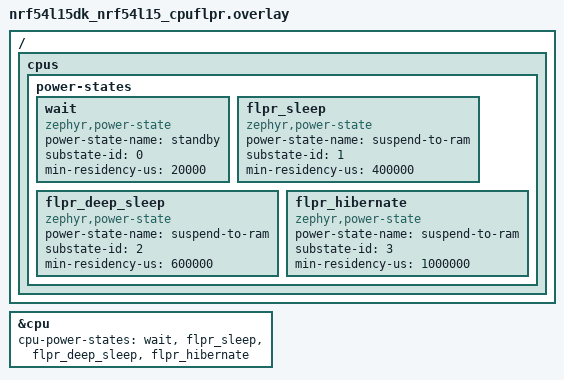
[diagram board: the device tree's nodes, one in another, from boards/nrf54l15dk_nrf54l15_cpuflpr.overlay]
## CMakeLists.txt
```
cmake_minimum_required(VERSION 3.20.0)

find_package(Zephyr REQUIRED HINTS $ENV{ZEPHYR_BASE})
project(remote)

message(DEBUG "Power mode handler for RISC-V is included.")
target_sources(app PRIVATE src/power_off.c)
target_sources(app PRIVATE src/main_flpr.c)
```

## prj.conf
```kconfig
CONFIG_LOG=y
CONFIG_CONSOLE=y
CONFIG_UART_CONSOLE=y
CONFIG_SERIAL=y
CONFIG_BOOT_BANNER=n
CONFIG_NCS_BOOT_BANNER=n
CONFIG_PRINTK=y

CONFIG_ASSERT=y
CONFIG_GPIO=y

CONFIG_PM=y
CONFIG_POWEROFF=y
CONFIG_PM_DEVICE=y
CONFIG_PM_DEVICE_RUNTIME=y
```

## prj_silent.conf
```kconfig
# Silent build - no logging overhead during power measurements.
CONFIG_LOG=n
CONFIG_CONSOLE=n
CONFIG_UART_CONSOLE=n
CONFIG_SERIAL=n
CONFIG_BOOT_BANNER=n
CONFIG_NCS_BOOT_BANNER=n

CONFIG_ASSERT=y
CONFIG_GPIO=y

CONFIG_PM=y
CONFIG_POWEROFF=y
CONFIG_PM_DEVICE=y
CONFIG_PM_DEVICE_RUNTIME=y
```

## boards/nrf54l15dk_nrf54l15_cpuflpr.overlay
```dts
/*
 * Copyright (c) 2025 Nordic Semiconductor ASA
 *
 * SPDX-License-Identifier: LicenseRef-Nordic-5-Clause
 */

/ {
	cpus {
		power-states {
			wait: wait {
				compatible = "zephyr,power-state";
				power-state-name = "standby";
				substate-id = <0>;
				min-residency-us = <20000>;
			};

			flpr_sleep: flpr_sleep {
				compatible = "zephyr,power-state";
				power-state-name = "suspend-to-ram";
				substate-id = <1>;
				min-residency-us = <400000>;
			};

			flpr_deep_sleep: flpr_deep_sleep {
				compatible = "zephyr,power-state";
				power-state-name = "suspend-to-ram";
				substate-id = <2>;
				min-residency-us = <600000>;
			};

			flpr_hibernate: flpr_hibernate {
				compatible = "zephyr,power-state";
				power-state-name = "suspend-to-ram";
				substate-id = <3>;
				min-residency-us = <1000000>;
			};
		};
	};
};

&cpu {
	cpu-power-states = <&wait &flpr_sleep &flpr_deep_sleep &flpr_hibernate>;
};
```

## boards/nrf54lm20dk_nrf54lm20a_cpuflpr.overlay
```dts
/*
 * Copyright (c) 2025 Nordic Semiconductor ASA
 *
 * SPDX-License-Identifier: LicenseRef-Nordic-5-Clause
 */

/ {
	cpus {
		power-states {
			wait: wait {
				compatible = "zephyr,power-state";
				power-state-name = "standby";
				substate-id = <0>;
				min-residency-us = <2000>;
			};

			flpr_sleep: flpr_sleep {
				compatible = "zephyr,power-state";
				power-state-name = "suspend-to-ram";
				substate-id = <1>;
				min-residency-us = <400000>;
			};

			flpr_deep_sleep: flpr_deep_sleep {
				compatible = "zephyr,power-state";
				power-state-name = "suspend-to-ram";
				substate-id = <2>;
				min-residency-us = <600000>;
			};

			flpr_hibernate: flpr_hibernate {
				compatible = "zephyr,power-state";
				power-state-name = "suspend-to-ram";
				substate-id = <3>;
				min-residency-us = <1000000>;
			};
		};
	};
};

&cpu {
	cpu-power-states = <&wait &flpr_sleep &flpr_deep_sleep &flpr_hibernate>;
};
```

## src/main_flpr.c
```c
#include <zephyr/kernel.h>
#include <zephyr/logging/log.h>
#include <zephyr/drivers/gpio.h>

LOG_MODULE_REGISTER(flpr_sleep_test, LOG_LEVEL_INF);

/*
 * FLPR core image - shared by nRF54H20, nRF54LM20A and nRF54L15.
 *
 * Active phase: quadratic computation (ax² + bx + c) to simulate a
 * realistic RISC-V workload using MUL/ADD instructions.
 * Tune COMPUTE_ITERATIONS to achieve ~1-2 ms active time at the FLPR
 * clock frequency - verify the pulse width on a PPK trace.
 *
 * PM selects the sleep state based on TEST_SLEEP_DURATION_MS vs the
 * min-residency-us values defined in the board FLPR overlay:
 *   300 ms  -> WAIT        (substate 0, min-residency  20 ms)
 *   500 ms  -> SLEEP       (substate 1, min-residency 400 ms)
 *   800 ms  -> DEEP_SLEEP  (substate 2, min-residency 600 ms)
 *   1200 ms -> HIBERNATE   (substate 3, min-residency 1000 ms)
 *
 * Note: nRF54H20 FLPR has only two power states (wait / suspend-to-ram).
 *
 * Baseline mode (CONFIG_TEST_BASELINE_SLEEP=y):
 *   FLPR sleeps forever - no compute, no GRTC wakeup.  Used to measure
 *   the true system current floor.
 */



#define COMPUTE_ITERATIONS 65000
#define BUSY_WAIT_INTERVAL 5000

static const struct gpio_dt_spec boot_led = GPIO_DT_SPEC_GET(DT_ALIAS(led0), gpios);

int main(void)
{
#if defined(CONFIG_TEST_BASELINE_SLEEP)
	while (1) {
		k_sleep(K_FOREVER);
	}
#else
	int counter = 0;

	/* Brief LED flash on boot so FLPR startup is visible on a PPK trace. */
	if (gpio_is_ready_dt(&boot_led)) {
		gpio_pin_configure_dt(&boot_led, GPIO_OUTPUT_INACTIVE);
		gpio_pin_set_dt(&boot_led, 1);
		k_busy_wait(5000); /* 5 ms */
		gpio_pin_set_dt(&boot_led, 0);
	}

	LOG_INF("Multicore flpr_sleep_test on %s", CONFIG_BOARD_TARGET);
	LOG_INF("Main sleeps for %d ms", CONFIG_TEST_SLEEP_DURATION_MS);

	while (1) {
		volatile uint32_t result = 0;

		for (uint32_t i = 0; i < COMPUTE_ITERATIONS; i++) {
			result += (i * i) + (3 * i) + 7;
		}

		LOG_INF("Run %d (result=%u)", counter, (unsigned int)result);
		counter++;
		/*
		k_busy_wait(BUSY_WAIT_INTERVAL);
		*/
		k_msleep(CONFIG_TEST_SLEEP_DURATION_MS);
	}
#endif /* CONFIG_TEST_BASELINE_SLEEP */

	return 0;
}
```

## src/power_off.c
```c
#include <zephyr/kernel.h>
#include <zephyr/pm/pm.h>
#include <zephyr/devicetree.h>
#include <hal/nrf_vpr_csr.h>

#include <zephyr/logging/log.h>
LOG_MODULE_REGISTER(power_off, LOG_LEVEL_INF);

#define VIPER_SLEEP_SUBSTATE_WAIT 0

#if defined(CONFIG_SOC_NRF54H20_CPUFLPR)
/* nRF54H20 FLPR has two sleep states:
 *   0 = HIBERNATE  (PM_STATE_SUSPEND_TO_RAM)  context saved, core resets on wakeup
 *   1 = DEEPSLEEP  (PM_STATE_SUSPEND_TO_RAM)  noop
 */
#define VIPER_SLEEP_SUBSTATE_HIBERNATE 0
#define VIPER_SLEEP_SUBSTATE_DEEPSLEEP 1
#else
/* All other FLPR cores (nRF54LM20A, nRF54L15) have four sleep states:
 *   0 = WAIT       (PM_STATE_STANDBY)         clock gated, fast wakeup
 *   1 = SLEEP      (PM_STATE_SUSPEND_TO_RAM)  clock off, RAM on, resumable
 *   2 = DEEP_SLEEP (PM_STATE_SUSPEND_TO_RAM)  clock off, RAM retained, resumable
 *   3 = HIBERNATE  (PM_STATE_SUSPEND_TO_RAM)  power off, context saved, resets on wakeup
 */
#define VIPER_SLEEP_SUBSTATE_SLEEP      1
#define VIPER_SLEEP_SUBSTATE_DEEP_SLEEP 2
#define VIPER_SLEEP_SUBSTATE_HIBERNATE  3
#endif

static void pm_go_to_wait(void)
{
	LOG_INF("Wait state");

	csr_write(VPRCSR_NORDIC_VPRNORDICSLEEPCTRL,
		  VPRCSR_NORDIC_VPRNORDICSLEEPCTRL_SLEEPSTATE_WAIT);
	nrf_barrier_w();
	arch_cpu_idle();
}

#if !defined(CONFIG_SOC_NRF54H20_CPUFLPR)
static void pm_go_to_sleep(void)
{
	LOG_INF("Sleep state");

	csr_write(VPRCSR_NORDIC_VPRNORDICSLEEPCTRL,
		  VPRCSR_NORDIC_VPRNORDICSLEEPCTRL_SLEEPSTATE_SLEEP);
	nrf_barrier_w();
	arch_cpu_idle();
}

static void pm_go_to_deep_sleep(void)
{
	LOG_INF("Deep sleep state");

	csr_write(VPRCSR_NORDIC_VPRNORDICSLEEPCTRL,
		  VPRCSR_NORDIC_VPRNORDICSLEEPCTRL_SLEEPSTATE_DEEPSLEEP);
	nrf_barrier_w();
	arch_cpu_idle();
}
#endif

static void pm_go_to_hibernate(void)
{
	LOG_INF("Hibernate state (core resets on wakeup)");

	csr_write(VPRCSR_NORDIC_VPRNORDICSLEEPCTRL,
		  VPRCSR_NORDIC_VPRNORDICSLEEPCTRL_SLEEPSTATE_HIBERNATE);
	nrf_barrier_w();
	arch_cpu_idle();
}

void pm_state_set(enum pm_state state, uint8_t substate_id)
{
	LOG_INF("pm_state_set: %d %d", (int)state, (int)substate_id);

	switch (state) {
	case PM_STATE_STANDBY:
		switch (substate_id) {
		case VIPER_SLEEP_SUBSTATE_WAIT:
			pm_go_to_wait();
			break;
		}
		break;
	case PM_STATE_SUSPEND_TO_RAM:
		switch (substate_id) {
#if defined(CONFIG_SOC_NRF54H20_CPUFLPR)
		case VIPER_SLEEP_SUBSTATE_HIBERNATE:
			pm_go_to_hibernate();
			break;
		case VIPER_SLEEP_SUBSTATE_DEEPSLEEP:
			/* noop */
			break;
#else
		case VIPER_SLEEP_SUBSTATE_SLEEP:
			pm_go_to_sleep();
			break;
		case VIPER_SLEEP_SUBSTATE_DEEP_SLEEP:
			pm_go_to_deep_sleep();
			break;
		case VIPER_SLEEP_SUBSTATE_HIBERNATE:
			pm_go_to_hibernate();
			break;
#endif
		}
		break;
	default:
		break;
	}
}

void pm_state_exit_post_ops(enum pm_state state, uint8_t substate_id)
{
	LOG_INF("pm_state_exit_post_ops");
	ARG_UNUSED(state);
	ARG_UNUSED(substate_id);

	csr_write(VPRCSR_NORDIC_VPRNORDICSLEEPCTRL,
		  VPRCSR_NORDIC_VPRNORDICSLEEPCTRL_SLEEPSTATE_WAIT);

	irq_unlock(MSTATUS_IEN);
}
```
